# SAMA7G54D1G device description
Architecture: CORTEX-A7; Family: SAMA; Series: SAMA7G
Registers are 32-bit, read-write, reset 0x0 unless marked. A register's access mark holds for its fields unless they carry their own. Offsets are from the block's base; [hi:lo] are bit positions; {n}, {i} and the like mark numbered series; 'fields as' and 'values as' point back to an identical list.

## CPKCC — Classic Public Key Cryptography Controller
Instances: CPKCC 0xE000C000
0x00 CPKCC_R reset not defined — R Parameter Register
  [31:0] VALUE — CPKCC_R value
0x04 CPKCC_X reset not defined — X Parameter Register
  [31:0] VALUE — CPKCC_X value
0x08 CPKCC_Y reset not defined — Y Parameter Register
  [31:0] VALUE — CPKCC_Y value
0x0C CPKCC_Z reset not defined — Z Parameter Register
  [31:0] VALUE — CPKCC_Z value
0x10 CPKCC_J reset not defined — J Parameter Register
  [31:0] VALUE — CPKCC_J value
0x14 CPKCC_K reset not defined — K Parameter Register
  [31:0] VALUE — CPKCC_K value
0x18 CPKCC_N reset not defined — N Parameter Register
  [31:0] VALUE — CPKCC_N value
0x1C CPKCC_SMULA reset not defined — SMULA Register
  [31:0] VALUE — CPKCC_SMULA value
0x20 CPKCC_SMULB reset not defined — SMULB Register
  [31:0] VALUE — CPKCC_SMULB value
0x24 CPKCC_SMULRL reset not defined — SMULRL Register
  [31:0] VALUE — CPKCC_SMULRL value
0x28 CPKCC_SMULRH reset not defined — SMULRH Register
  [31:0] VALUE — CPKCC_SMULRH value
0x2C CPKCC_IDLE 8-bit reset not defined — IDLE Register
  [7:0] VALUE — CPKCC_IDLE value
0x2D CPKCC_IDLECACHE 8-bit reset not defined — IDLECACHE Register
  [7:0] VALUE — CPKCC_IDLECACHE value
0x30 CPKCC_CR_C reset not defined — CR_C Register
  [31:0] VALUE — CPKCC_CR_C value
0x34 CPKCC_CR_S reset not defined — CR_S Register
  [31:0] VALUE — CPKCC_CR_S value
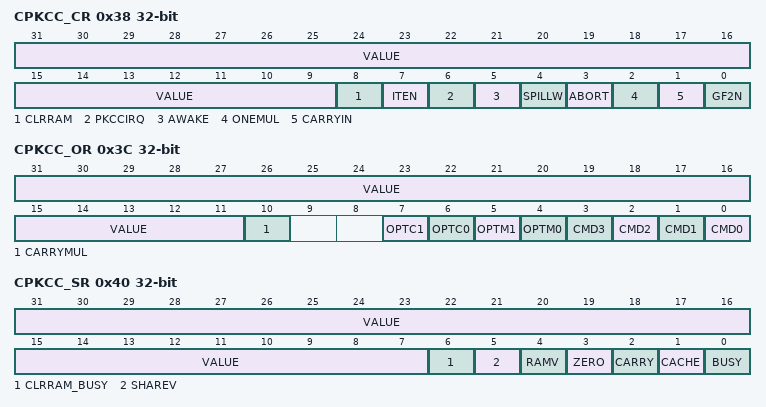
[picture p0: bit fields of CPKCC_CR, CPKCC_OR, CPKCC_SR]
0x38 CPKCC_CR reset not defined — CR Register
  [31:9] VALUE — CPKCC_CR value
  [8] CLRRAM — CLRRAM value
  [7] ITEN — ITEN value
  [6] PKCCIRQ — CPKCC_IRQ value
  [5] AWAKE — AWAKE value
  [4] SPILLW — Spill Word register bit
  [3] ABORT — ABORT value
  [2] ONEMUL — ONEMUL value
  [1] CARRYIN — CARRYIN value
  [0] GF2N — GF(2n) mode
0x3C CPKCC_OR reset not defined — Operation Register
  [31:11] VALUE — CPKCC_OR value
  [10] CARRYMUL — CARRYMUL value
  [7] OPTC1 — OPTC1 value
  [6] OPTC0 — OPTC0 value
  [5] OPTM1 — OPTM1 value
  [4] OPTM0 — OPTM0 value
  [n] CMD{n} (n=0..3) — CMD{n} value
0x40 CPKCC_SR reset not defined — SR Register
  [31:7] VALUE — CPKCC_SR value
  [6] CLRRAM_BUSY — CLRRAM_BUSY value
  [5] SHAREV — SHAREV value
  [4] RAMV — RAM violation
  [3] ZERO — ZERO value
  [2] CARRY — CARRY value
  [1] CACHE — CACHE value
  [0] BUSY — BUSY value
0xEC CPKCC_ADDRSIZE reset not defined — ADDRSIZE Register
  [31:0] VALUE — CPKCC_ADDRSIZE value
{0xF0+4i} CPKCC_IPNAME[{i}] (i=0..1) reset not defined — IPNAME1 Register
  [31:0] VALUE — CPKCC_IPNAME1 value
0xF8 CPKCC_FEATURES reset not defined — FEATURES Register
  [31:0] VALUE — CPKCC_FEATURES value

## EIC — External Interrupt Controller
Instances: EIC 0xE1628000
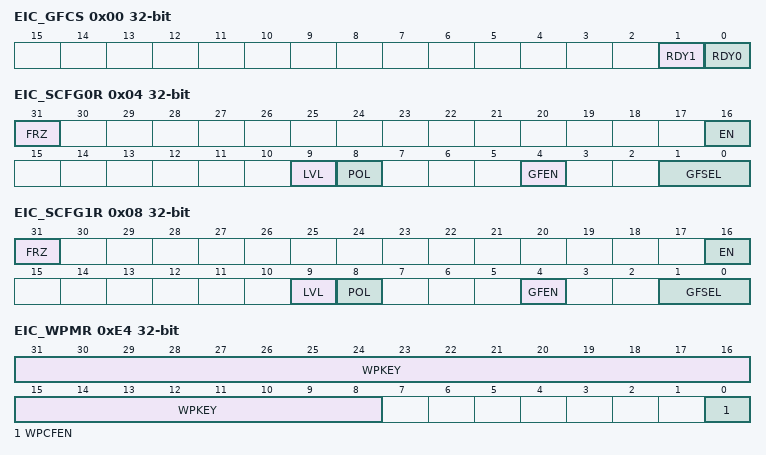
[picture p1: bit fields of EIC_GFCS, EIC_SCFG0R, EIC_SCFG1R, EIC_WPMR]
0x00 EIC_GFCS ro — Glitch Filter Configuration Status Register
  [1] RDY1 — Filter 1 Configuration Ready
    0=The interrupt line x glitch filter is not yet ready for use due to a previous write to IP_Acronym_SCFGxR, or the glitch filter is not implemented for this interrupt line. The glitch filter must not be reprogrammed in EIC_SCFGxR.; 1=The interrupt line x glitch filter configuration is done and the glitch filter is active. The glitch filter can be programmed in EIC_SCFGxR.
  [0] RDY0 — Filter 0 Configuration Ready
    values as RDY1
0x04 EIC_SCFG0R reset not defined — Source Configuration Register 0
  [31] FRZ — Interrupt Line Freeze
    0=No effect; 1=EIC_SCFGxR is frozen until hardware reset
  [16] EN — Source Enable
    0=The EIC source x is disabled. Any source edge or level detection is discarded.; 1=The EIC source x is enabled
  [9] LVL — Level Detection
    0=The EIC source x interrupt status is set on a valid source edge; 1=The EIC source x interrupt status is set on a valid source level
  [8] POL — Polarity
    0=The EIC source x is active low if LVL is set, or active on falling edge if LVL is cleared; 1=The EIC source x is active high if LVL is set, or active on rising edge if LVL is cleared
  [4] GFEN — Glitch Filter Enable
    0=The glitch filter is disabled or not implemented for EIC source x. Any source x change is forwarded as is to the source detection logic.; 1=The glitch filter is enabled for EIC source x. The EIC source x glitches are filtered according to Section 7.1 "Interrupt Line Characteristics".
  [1:0] GFSEL — Glitch Filter Selector
0x08 EIC_SCFG1R reset not defined — Source Configuration Register 1
  fields as EIC_SCFG0R
0xE4 EIC_WPMR — Write Protection Mode Register
  [31:8] WPKEY — Write Protection Key
    0x454943=PASSWD (Writing any other value in this field aborts the write operation of the WPCFEN and WPITEN bit. Always reads as 0.)
  [0] WPCFEN — Write Protection Configuration Enable
    0=Disables the write protection of the configuration registers if WPKEY corresponds to 0x454943 ("EIC" in ASCII); 1=Enables the write protection of the configuration registers if WPKEY corresponds to 0x454943 ("EIC" in ASCII)
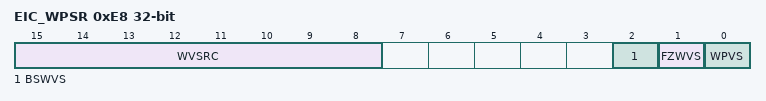
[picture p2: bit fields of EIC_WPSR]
0xE8 EIC_WPSR ro — Write Protection Status Register
  [15:8] WVSRC — Write Violation Source
  [2] BSWVS — Busy Register Write Violation Status
    0=No write access violation of a busy register has occurred since the last read of the EIC_WPSR; 1=A write access violation of a busy register has occurred since the last read of the EIC_WPSR. The associated violation is reported into field WVSRC.
  [1] FZWVS — Frozen Register Write Violation Status
    0=No write access violation of a frozen register has occurred since the last read of the EIC_WPSR; 1=A write access violation of a frozen register has occurred since the last read of the EIC_WPSR. The associated violation is reported into field WVSRC.
  [0] WPVS — Write Protection Register Violation Status
    0=No write protection violation has occurred since the last read of the EIC_WPSR; 1=A write protection violation has occurred since the last read of the EIC_WPSR. The associated violation is reported into field WVSRC.
